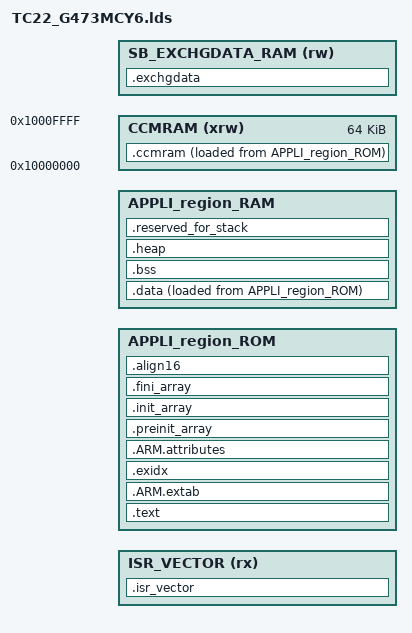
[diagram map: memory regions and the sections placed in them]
/* Generated by LinkerScriptGenerator [http://visualgdb.com/tools/LinkerScriptGenerator]
 * Target: STM32G473VET6
 * The file is provided under the BSD license.
 */

/* Entry Point */
ENTRY(Reset_Handler)

/* Highest address of the user mode stack */
_estack = 0x2001FF00;    /* end of SB_SRAM1*/
/* Generate a link error if heap and stack don't fit into RAM */
_Min_Heap_Size = 0x200;      /* required amount of heap  */
_Min_Stack_Size = 0x800; /* required amount of stack */
INCLUDE ../Core/Startup/TC22_G473MCY6_mapping_fwimg.ld
INCLUDE ../Core/Startup/TC22_G473MCY6_mapping_sbsfu.ld

_SBSFU_FwHeaderSize_ = 0x200; /* FwHeaderSize, Offset for FwActiveSlot (Optimised LORCH Header) */

/* Specify the memory areas */
__ICFEDIT_intvec_start__  = __ICFEDIT_SLOT_Active_1_start__    + _SBSFU_FwHeaderSize_;
APPLI_region_ROM_start    = __ICFEDIT_SLOT_Active_1_start__    + VECTOR_SIZE + _SBSFU_FwHeaderSize_;
APPLI_region_ROM_length   = __ICFEDIT_SLOT_Active_1_end__    - APPLI_region_ROM_start + 1;
APPLI_region_RAM_start    = __ICFEDIT_SE_region_RAM_end__ + 1;
APPLI_region_RAM_length    = 0x2001D000 - APPLI_region_RAM_start;
MEMORY
{
 ISR_VECTOR (rx)   : ORIGIN = __ICFEDIT_intvec_start__, LENGTH = VECTOR_SIZE
 APPLI_region_ROM  : ORIGIN = APPLI_region_ROM_start, LENGTH = APPLI_region_ROM_length
 APPLI_region_RAM  : ORIGIN = APPLI_region_RAM_start, LENGTH = APPLI_region_RAM_length
 CCMRAM (xrw) : ORIGIN = 0x10000000, LENGTH = 64K
 SB_EXCHGDATA_RAM (rw) 	   	   : ORIGIN = __ICFEDIT_EXCHGDATA_RAM_start__, LENGTH = __ICFEDIT_EXCHGDATA_RAM_length__

}


SECTIONS
{
.isr_vector :
{
    . = ALIGN(8);
    KEEP(*(.isr_vector)) /* Startup code */
    FILL(0);
    . = ORIGIN(ISR_VECTOR) + LENGTH(ISR_VECTOR) - 1;
    BYTE(0)
    . = ALIGN(8);

} > ISR_VECTOR

/*--- New CCMRAM linker section definition ---*/
 _siccmram = LOADADDR(.ccmram);
 /* CCMRAM section */
 .ccmram :
 {
 . = ALIGN(4);
 _sccmram = .; /* define a global symbols at ccmram start */
 *(.ccmram)
 *(.ccmram*)
 . = ALIGN(4);
 _eccmram = .; /* define a global symbols at ccmram end */
 } >CCMRAM AT> APPLI_region_ROM

 /*--- End of CCMRAM linker section definition ---*/

	.text :
	{
		. = ALIGN(4);
		_stext = .;

		*(.text)
		*(.text*)
		*(.rodata)
		*(.rodata*)
		*(.glue_7)
		*(.glue_7t)
		KEEP(*(.init))
		KEEP(*(.fini))
		. = ALIGN(8);
		_etext = .;

	} > APPLI_region_ROM

	.ARM.extab :
	{
		. = ALIGN(8);
		*(.ARM.extab)
		*(.gnu.linkonce.armextab.*)
		. = ALIGN(8);
	} > APPLI_region_ROM

	.exidx :
	{
		. = ALIGN(8);
		PROVIDE(__exidx_start = .);
		*(.ARM.exidx*)
		. = ALIGN(8);
		PROVIDE(__exidx_end = .);
	} > APPLI_region_ROM

	.ARM.attributes :
	{
		*(.ARM.attributes)
	} > APPLI_region_ROM

	.preinit_array :
	{
		. = ALIGN(8);
		PROVIDE_HIDDEN(__preinit_array_start = .);
		KEEP(*(.preinit_array*))
		PROVIDE_HIDDEN(__preinit_array_end = .);
		. = ALIGN(8);
	} > APPLI_region_ROM

	.init_array :
	{
		. = ALIGN(8);
		PROVIDE_HIDDEN(__init_array_start = .);
		KEEP(*(SORT(.init_array.*)))
		KEEP(*(.init_array*))
		PROVIDE_HIDDEN(__init_array_end = .);
		. = ALIGN(8);
	} > APPLI_region_ROM

	.fini_array :
	{
		. = ALIGN(8);
		PROVIDE_HIDDEN(__fini_array_start = .);
		KEEP(*(.fini_array*))
		KEEP(*(SORT(.fini_array.*)))
		PROVIDE_HIDDEN(__fini_array_end = .);
		. = ALIGN(8);
	} > APPLI_region_ROM

	.data :
	{
		. = ALIGN(8);
		_sdata = .;

		/* PROVIDE(__data_start__ = _sdata); */
		*(.data)
		*(.data*)
		. = ALIGN(8);
		_edata = .;

	/*	PROVIDE(__data_end__ = _edata);  */
	} > APPLI_region_RAM AT >APPLI_region_ROM

	_sidata = LOADADDR(.data);
	
	  /* Extra ROM section (last one) to make sure the binary size is a multiple of the AES block size (16 bytes) and G4 flash writing unit (8 bytes)*/
  .align16 :
  {
    . = . + 1;         /* _edata=. is aligned on 8 bytes so could be aligned on 16 bytes: add 1 byte gap */
    . = ALIGN(16) - 1; /* increment the location counter until next 16 bytes aligned address (-1 byte)   */
    BYTE(0);           /* allocate 1 byte (value is 0) to be a multiple of 16 bytes                      */
  } >  APPLI_region_ROM
  
  /* Uninitialized data section */
	.bss :
	{
		. = ALIGN(8);
		_sbss = .;

		PROVIDE(__bss_start__ = _sbss);
		*(.bss)
		*(.bss*)
		*(COMMON)
		. = ALIGN(8);
		_ebss = .;

		PROVIDE(__bss_end__ = _ebss);
	} > APPLI_region_RAM

	PROVIDE(end = .);

	.heap (NOLOAD) :
	{
		. = ALIGN(8);
		PROVIDE(__heap_start__ = .);
		KEEP(*(.heap))
		. = ALIGN(8);
		PROVIDE(__heap_end__ = .);
	} > APPLI_region_RAM

	.reserved_for_stack (NOLOAD) :
	{
		. = ALIGN(8);
		PROVIDE(__reserved_for_stack_start__ = .);
		KEEP(*(.reserved_for_stack))
		. = ALIGN(8);
		PROVIDE(__reserved_for_stack_end__ = .);
	} > APPLI_region_RAM
	
	  /* ExchangeData RAM Bereich */
	  .exchgdata (NOLOAD):
	  {
			. = ALIGN(4);
			_exchgdata_start = .;
			*(.exchgdata)
			*(.exchgdata.*)
			. = ALIGN(4);
			_exchgdata_end = .;
	  } >SB_EXCHGDATA_RAM

}

